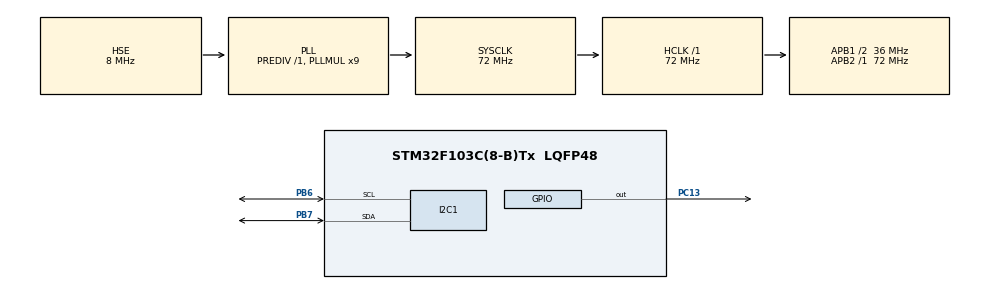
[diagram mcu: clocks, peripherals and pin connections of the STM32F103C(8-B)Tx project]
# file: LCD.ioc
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FREERTOS.Tasks01=defaultTask,24,128,StartDefaultTask,Default,NULL,Dynamic,NULL,NULL;sensor,8,128,entrySensor1,Default,NULL,Dynamic,NULL,NULL;NOMBRE,8,128,NombreApellido,Default,NULL,Dynamic,NULL,NULL
I2C1.I2C_Mode=I2C_Fast
Mcu.Family=STM32F1
Mcu.Name=STM32F103C(8-B)Tx
Mcu.Package=LQFP48
NVIC.PriorityGroup=NVIC_PRIORITYGROUP_4
PA13.Mode=Serial_Wire
PA13.Signal=SYS_JTMS-SWDIO
PA14.Mode=Serial_Wire
PA14.Signal=SYS_JTCK-SWCLK
PB6.Mode=I2C
PB6.Signal=I2C1_SCL
PB7.Mode=I2C
PB7.Signal=I2C1_SDA
PC13-TAMPER-RTC.Signal=GPIO_Output
PD0-OSC_IN.Mode=HSE-External-Oscillator
PD0-OSC_IN.Signal=RCC_OSC_IN
PD1-OSC_OUT.Mode=HSE-External-Oscillator
PD1-OSC_OUT.Signal=RCC_OSC_OUT
ProjectManager.HeapSize=0x200
ProjectManager.StackSize=0x400
ProjectManager.TargetToolchain=STM32CubeIDE
RCC.AHBFreq_Value=72000000
RCC.APB1CLKDivider=RCC_HCLK_DIV2
RCC.APB1Freq_Value=36000000
RCC.APB1TimFreq_Value=72000000
RCC.APB2Freq_Value=72000000
RCC.APB2TimFreq_Value=72000000
RCC.HCLKFreq_Value=72000000
RCC.PLLMUL=RCC_PLL_MUL9
RCC.PLLSourceVirtual=RCC_PLLSOURCE_HSE
RCC.SYSCLKFreq_VALUE=72000000
RCC.SYSCLKSource=RCC_SYSCLKSOURCE_PLLCLK
RCC.USBFreq_Value=72000000
VP_FREERTOS_VS_CMSIS_V2.Mode=CMSIS_V2
board=custom

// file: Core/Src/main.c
/* USER CODE BEGIN Header */
/**
  ******************************************************************************
  * @file           : main.c
  * @brief          : Main program body
  ******************************************************************************
  * @attention
  *
  * Copyright (c) 2022 STMicroelectronics.
  * All rights reserved.
  *
  * This software is licensed under terms that can be found in the LICENSE file
  * in the root directory of this software component.
  * If no LICENSE file comes with this software, it is provided AS-IS.
  *
  ******************************************************************************
  */
/* USER CODE END Header */
#include "main.h"
#include "cmsis_os.h"

/* USER CODE BEGIN Includes */
#include "fonts.h"
#include "ssd1306.h"
#include "task.h"
/* USER CODE END Includes */

I2C_HandleTypeDef hi2c1;

/* Definitions for defaultTask */
osThreadId_t defaultTaskHandle;
const osThreadAttr_t defaultTask_attributes = {
  .name = "defaultTask",
  .stack_size = 128 * 4,
  .priority = (osPriority_t) osPriorityNormal,
};
/* Definitions for sensor */
osThreadId_t sensorHandle;
const osThreadAttr_t sensor_attributes = {
  .name = "sensor",
  .stack_size = 128 * 4,
  .priority = (osPriority_t) osPriorityLow,
};
/* Definitions for NOMBRE */
osThreadId_t NOMBREHandle;
const osThreadAttr_t NOMBRE_attributes = {
  .name = "NOMBRE",
  .stack_size = 128 * 4,
  .priority = (osPriority_t) osPriorityLow,
};

void SystemClock_Config(void);
static void MX_GPIO_Init(void);
static void MX_I2C1_Init(void);
void StartDefaultTask(void *argument);
void entrySensor1(void *argument);
void NombreApellido(void *argument);

/* USER CODE BEGIN PFP */
void ImprimirLinea(char *s, uint8_t linea);
//void StartDefaultTask(void *argument);
/* USER CODE END PFP */

int main(void)
{

  /* MCU Configuration--------------------------------------------------------*/

  /* Reset of all peripherals, Initializes the Flash interface and the Systick. */
  HAL_Init();

  /* Configure the system clock */
  SystemClock_Config();

  /* Initialize all configured peripherals */
  MX_GPIO_Init();
  MX_I2C1_Init();
  /* USER CODE BEGIN 2 */
  //ssd1306_I2C_Init();
  SSD1306_Init();
  SSD1306_Clear();
  /* USER CODE END 2 */

  /* Init scheduler */
  osKernelInitialize();

  /* Create the thread(s) */
  /* creation of defaultTask */
  defaultTaskHandle = osThreadNew(StartDefaultTask, NULL, &defaultTask_attributes);

  /* creation of sensor */
  sensorHandle = osThreadNew(entrySensor1, NULL, &sensor_attributes);

  /* creation of NOMBRE */
  NOMBREHandle = osThreadNew(NombreApellido, NULL, &NOMBRE_attributes);

  /* Start scheduler */
  osKernelStart();

  /* We should never get here as control is now taken by the scheduler */
  /* Infinite loop */
  while (1)
  {

  }
}

void SystemClock_Config(void)
{
  RCC_OscInitTypeDef RCC_OscInitStruct = {0};
  RCC_ClkInitTypeDef RCC_ClkInitStruct = {0};

  /** Initializes the RCC Oscillators according to the specified parameters
  * in the RCC_OscInitTypeDef structure.
  */
  RCC_OscInitStruct.OscillatorType = RCC_OSCILLATORTYPE_HSE;
  RCC_OscInitStruct.HSEState = RCC_HSE_ON;
  RCC_OscInitStruct.HSEPredivValue = RCC_HSE_PREDIV_DIV1;
  RCC_OscInitStruct.HSIState = RCC_HSI_ON;
  RCC_OscInitStruct.PLL.PLLState = RCC_PLL_ON;
  RCC_OscInitStruct.PLL.PLLSource = RCC_PLLSOURCE_HSE;
  RCC_OscInitStruct.PLL.PLLMUL = RCC_PLL_MUL9;
  if (HAL_RCC_OscConfig(&RCC_OscInitStruct) != HAL_OK)
  {
    Error_Handler();
  }

  /** Initializes the CPU, AHB and APB buses clocks
  */
  RCC_ClkInitStruct.ClockType = RCC_CLOCKTYPE_HCLK|RCC_CLOCKTYPE_SYSCLK
                              |RCC_CLOCKTYPE_PCLK1|RCC_CLOCKTYPE_PCLK2;
  RCC_ClkInitStruct.SYSCLKSource = RCC_SYSCLKSOURCE_PLLCLK;
  RCC_ClkInitStruct.AHBCLKDivider = RCC_SYSCLK_DIV1;
  RCC_ClkInitStruct.APB1CLKDivider = RCC_HCLK_DIV2;
  RCC_ClkInitStruct.APB2CLKDivider = RCC_HCLK_DIV1;

  if (HAL_RCC_ClockConfig(&RCC_ClkInitStruct, FLASH_LATENCY_2) != HAL_OK)
  {
    Error_Handler();
  }
}

static void MX_I2C1_Init(void)
{

  hi2c1.Instance = I2C1;
  hi2c1.Init.ClockSpeed = 400000;
  hi2c1.Init.DutyCycle = I2C_DUTYCYCLE_2;
  hi2c1.Init.OwnAddress1 = 0;
  hi2c1.Init.AddressingMode = I2C_ADDRESSINGMODE_7BIT;
  hi2c1.Init.DualAddressMode = I2C_DUALADDRESS_DISABLE;
  hi2c1.Init.OwnAddress2 = 0;
  hi2c1.Init.GeneralCallMode = I2C_GENERALCALL_DISABLE;
  hi2c1.Init.NoStretchMode = I2C_NOSTRETCH_DISABLE;
  if (HAL_I2C_Init(&hi2c1) != HAL_OK)
  {
    Error_Handler();
  }

}

static void MX_GPIO_Init(void)
{
  GPIO_InitTypeDef GPIO_InitStruct = {0};

  /* GPIO Ports Clock Enable */
  __HAL_RCC_GPIOC_CLK_ENABLE();
  __HAL_RCC_GPIOD_CLK_ENABLE();
  __HAL_RCC_GPIOA_CLK_ENABLE();
  __HAL_RCC_GPIOB_CLK_ENABLE();

  /*Configure GPIO pin Output Level */
  HAL_GPIO_WritePin(GPIOC, GPIO_PIN_13, GPIO_PIN_RESET);

  /*Configure GPIO pin : PC13 */
  GPIO_InitStruct.Pin = GPIO_PIN_13;
  GPIO_InitStruct.Mode = GPIO_MODE_OUTPUT_PP;
  GPIO_InitStruct.Pull = GPIO_NOPULL;
  GPIO_InitStruct.Speed = GPIO_SPEED_FREQ_LOW;
  HAL_GPIO_Init(GPIOC, &GPIO_InitStruct);

}

/* USER CODE BEGIN 4 */
void ImprimirLinea(char *s, uint8_t linea) {
	taskENTER_CRITICAL();
	/* "borra" la línea para poder escribir en limpio */
	SSD1306_GotoXY(0, 0 + 14 * (linea - 1));
	SSD1306_Puts(" ", &Font_7x10, 1);
	/* imprime la cadena */
	SSD1306_GotoXY(0, 0 + 14 * (linea - 1));
	SSD1306_Puts(s, &Font_7x10, 1);
	/*actualiza pantalla*/
	SSD1306_UpdateScreen();
	taskEXIT_CRITICAL();
}
/* USER CODE END 4 */

void StartDefaultTask(void *argument)
{
  /* USER CODE BEGIN 5 */

  /* Infinite loop */
	for (;;) {
		HAL_GPIO_TogglePin(GPIOC, GPIO_PIN_13);
		if (HAL_GPIO_ReadPin(GPIOC, GPIO_PIN_13)) {
			ImprimirLinea("LED = OFF", 1);
		} else {
			ImprimirLinea("LED = ON ", 1);
		}
		osDelay(1000);
	}

  /* USER CODE END 5 */
}

void entrySensor1(void *argument)
{
  /* USER CODE BEGIN entrySensor1 */

  /* Infinite loop */
	int sensor = 0;
	char val[20] = "sensor1 = ";
	for (;;) {
		/* convierte el valor del sensor a ascii y lo
		 concatena al final de "sensor2 = " */
		itoa(sensor, val + 10, 10);
		ImprimirLinea(val, 2);
		sensor++;
		osDelay(100);
	}

  /* USER CODE END entrySensor1 */
}

void NombreApellido(void *argument)
{
  /* USER CODE BEGIN NombreApellido */

	/* Infinite loop */
  int m=0;
	for(;;)
  {
		if (m==0) {
			ImprimirLinea("MOREYRA", 3);
			m=1;
		} else {
			ImprimirLinea("JUAN   ", 3);
			m=0;
		}
		osDelay(200);
  }

  /* USER CODE END NombreApellido */
}

void Error_Handler(void)
{
  __disable_irq();
  while (1)
  {
  }
}
